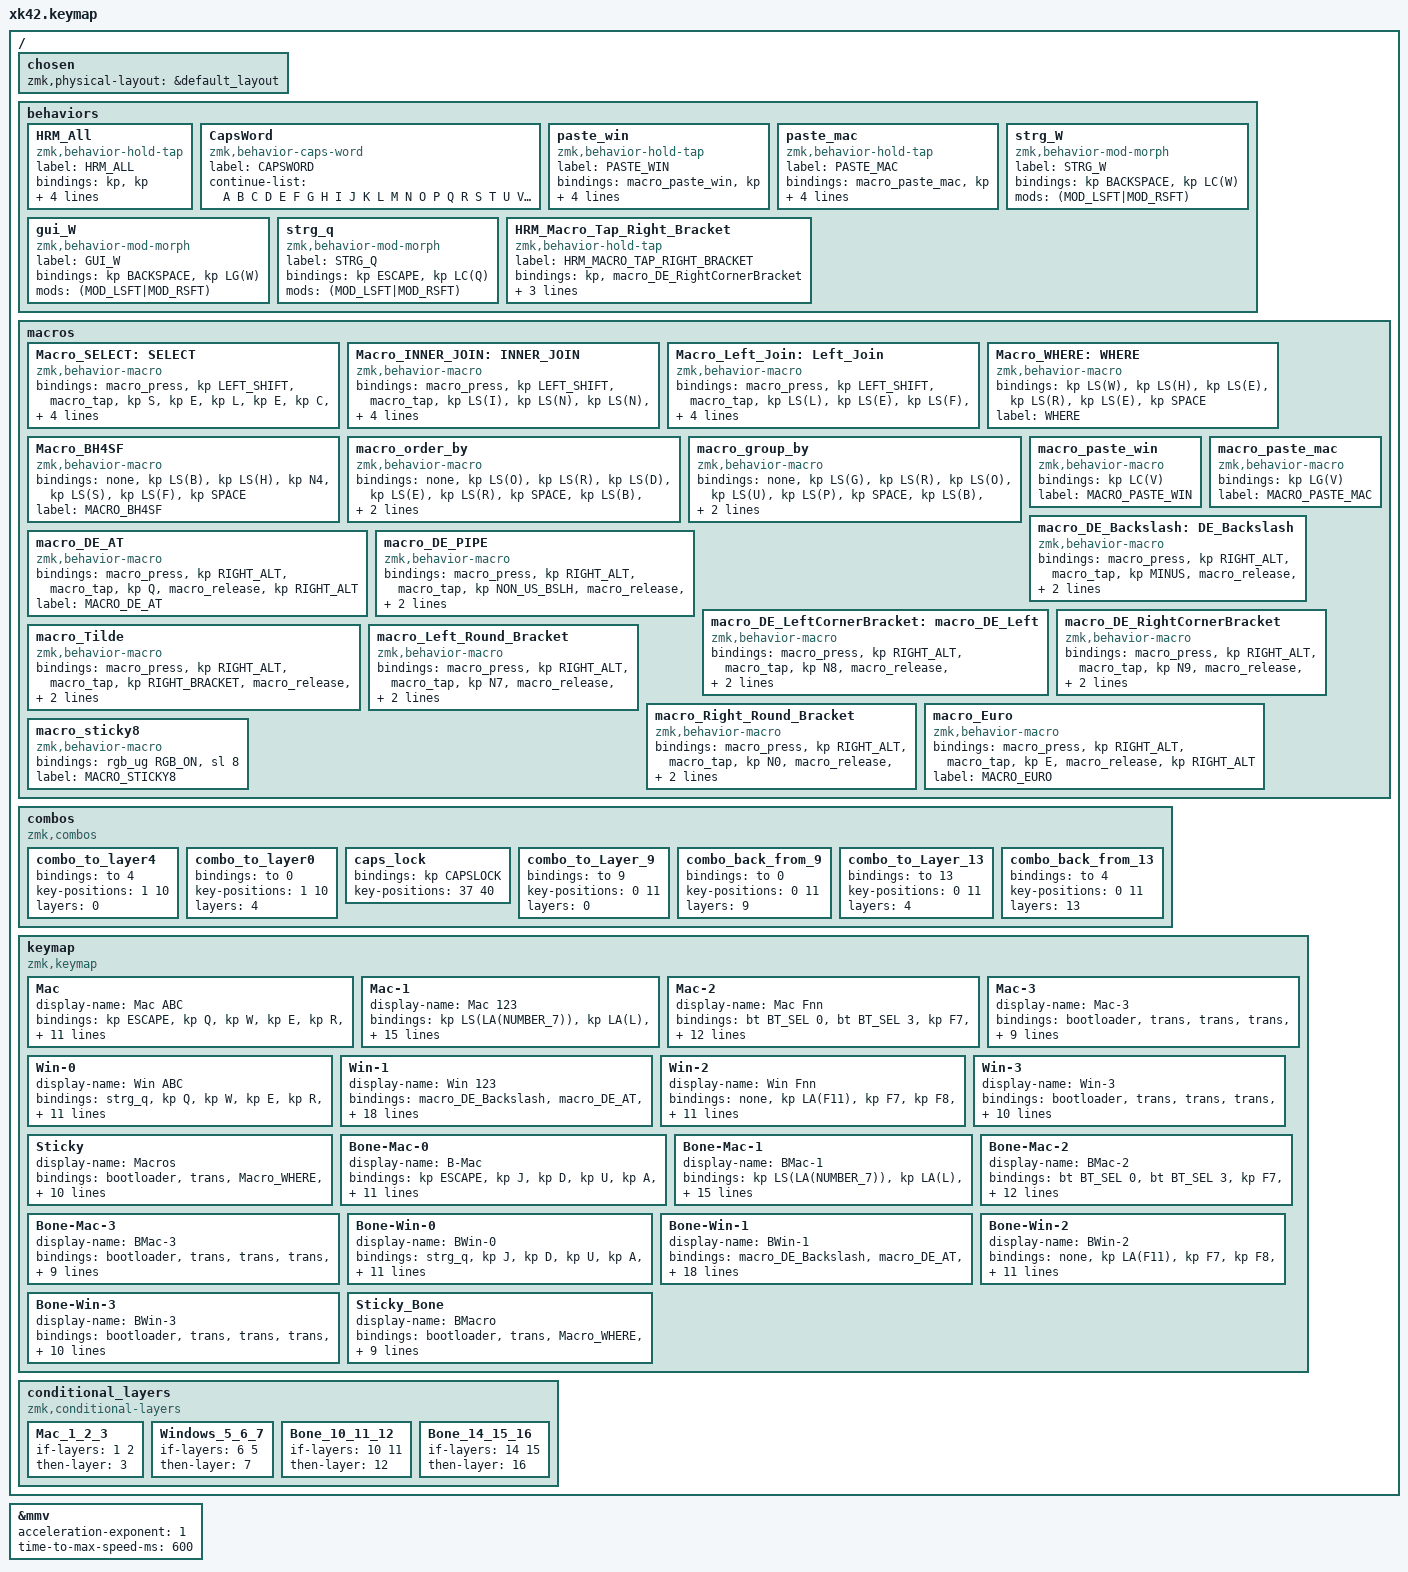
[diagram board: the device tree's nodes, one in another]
/*
 * Copyright (c) 2020 The ZMK Contributors
 *
 * SPDX-License-Identifier: MIT
 */

#define ZMK_POINTING_DEFAULT_MOVE_VAL 1500

#include <behaviors.dtsi>
#include <dt-bindings/zmk/bt.h>
#include <dt-bindings/zmk/keys.h>
#include <dt-bindings/zmk/pointing.h>
#include <dt-bindings/zmk/rgb.h>
#include "keys_de.h"

&mmv {
    acceleration-exponent = <1>;
    time-to-max-speed-ms = <600>;
};

/ {
    chosen { zmk,physical-layout = &default_layout; };

    behaviors {
        HRM_All: HRM_All {
            compatible = "zmk,behavior-hold-tap";
            label = "HRM_ALL";
            bindings = <&kp>, <&kp>;

            #binding-cells = <2>;
            tapping-term-ms = <200>;
            flavor = "balanced";
            require-prior-idle-ms = <150>;
            quick-tap-ms = <125>;
        };

        CapsWord: CapsWord {
            compatible = "zmk,behavior-caps-word";
            label = "CAPSWORD";
            #binding-cells = <0>;
            continue-list = <A B C D E F G H I J K L M N O P Q R S T U V W X Y Z SLASH QUESTION>;
        };

        paste_win: paste_win {
            compatible = "zmk,behavior-hold-tap";
            label = "PASTE_WIN";
            bindings = <&macro_paste_win>, <&kp>;

            #binding-cells = <2>;
            tapping-term-ms = <175>;
            flavor = "tap-preferred";
            require-prior-idle-ms = <125>;
            quick-tap-ms = <125>;
        };

        paste_mac: paste_mac {
            compatible = "zmk,behavior-hold-tap";
            label = "PASTE_MAC";
            bindings = <&macro_paste_mac>, <&kp>;

            #binding-cells = <2>;
            tapping-term-ms = <175>;
            flavor = "tap-preferred";
            require-prior-idle-ms = <125>;
            quick-tap-ms = <125>;
        };

        strg_W: strg_W {
            compatible = "zmk,behavior-mod-morph";
            label = "STRG_W";
            bindings = <&kp BACKSPACE>, <&kp LC(W)>;

            #binding-cells = <0>;
            mods = <(MOD_LSFT|MOD_RSFT)>;
        };

        gui_W: gui_W {
            compatible = "zmk,behavior-mod-morph";
            label = "GUI_W";
            bindings = <&kp BACKSPACE>, <&kp LG(W)>;

            #binding-cells = <0>;
            mods = <(MOD_LSFT|MOD_RSFT)>;
        };

        strg_q: strg_q {
            compatible = "zmk,behavior-mod-morph";
            label = "STRG_Q";
            bindings = <&kp ESCAPE>, <&kp LC(Q)>;

            #binding-cells = <0>;
            mods = <(MOD_LSFT|MOD_RSFT)>;
        };

        HRM_Macro_Tap_Right_Bracket: HRM_Macro_Tap_Right_Bracket {
            compatible = "zmk,behavior-hold-tap";
            label = "HRM_MACRO_TAP_RIGHT_BRACKET";
            bindings = <&kp>, <&macro_DE_RightCornerBracket>;

            #binding-cells = <2>;
            tapping-term-ms = <200>;
            flavor = "balanced";
            require-prior-idle-ms = <125>;
        };
    };

    macros {
        Macro_SELECT: SELECT {
            compatible = "zmk,behavior-macro";
            #binding-cells = <0>;
            bindings =
                <&macro_press>,
                <&kp LEFT_SHIFT>,
                <&macro_tap>,
                <&kp S &kp E &kp L &kp E &kp C &kp T &kp SPACE &kp DE_STAR &kp SPACE &kp F &kp R &kp O &kp M &kp SPACE>,
                <&macro_release>,
                <&kp LEFT_SHIFT &rgb_ug RGB_OFF>;

            label = "SELECT";
        };

        Macro_INNER_JOIN: INNER_JOIN {
            compatible = "zmk,behavior-macro";
            #binding-cells = <0>;
            bindings =
                <&macro_press>,
                <&kp LEFT_SHIFT>,
                <&macro_tap>,
                <&kp LS(I) &kp LS(N) &kp LS(N) &kp LS(E) &kp LS(R) &kp SPACE &kp LS(J) &kp LS(O) &kp LS(I) &kp LS(N) &kp SPACE>,
                <&macro_release>,
                <&kp LEFT_SHIFT &rgb_ug RGB_OFF>;

            label = "INNER_JOIN";
        };

        Macro_Left_Join: Left_Join {
            compatible = "zmk,behavior-macro";
            #binding-cells = <0>;
            bindings =
                <&macro_press>,
                <&kp LEFT_SHIFT>,
                <&macro_tap>,
                <&kp LS(L) &kp LS(E) &kp LS(F) &kp LS(T) &kp SPACE &kp LS(J) &kp LS(O) &kp LS(I) &kp LS(N) &kp SPACE>,
                <&macro_release>,
                <&kp LEFT_SHIFT>;

            label = "LEFT_JOIN";
        };

        Macro_WHERE: WHERE {
            compatible = "zmk,behavior-macro";
            #binding-cells = <0>;
            bindings = <&kp LS(W) &kp LS(H) &kp LS(E) &kp LS(R) &kp LS(E) &kp SPACE>;
            label = "WHERE";
        };

        Macro_BH4SF: Macro_BH4SF {
            compatible = "zmk,behavior-macro";
            #binding-cells = <0>;
            bindings = <&none &kp LS(B) &kp LS(H) &kp N4 &kp LS(S) &kp LS(F) &kp SPACE>;
            label = "MACRO_BH4SF";
        };

        macro_order_by: macro_order_by {
            compatible = "zmk,behavior-macro";
            #binding-cells = <0>;
            bindings = <&none &kp LS(O) &kp LS(R) &kp LS(D) &kp LS(E) &kp LS(R) &kp SPACE &kp LS(B) &kp LS(DE_Y)>;
            label = "MACRO_ORDER_BY";
        };

        macro_group_by: macro_group_by {
            compatible = "zmk,behavior-macro";
            #binding-cells = <0>;
            bindings = <&none &kp LS(G) &kp LS(R) &kp LS(O) &kp LS(U) &kp LS(P) &kp SPACE &kp LS(B) &kp LS(DE_Y)>;
            label = "MACRO_GROUP_BY";
        };

        macro_paste_win: macro_paste_win {
            compatible = "zmk,behavior-macro";
            #binding-cells = <0>;
            bindings = <&kp LC(V)>;
            label = "MACRO_PASTE_WIN";
        };

        macro_paste_mac: macro_paste_mac {
            compatible = "zmk,behavior-macro";
            #binding-cells = <0>;
            bindings = <&kp LG(V)>;
            label = "MACRO_PASTE_MAC";
        };

        macro_DE_Backslash: DE_Backslash {
            compatible = "zmk,behavior-macro";
            #binding-cells = <0>;
            bindings =
                <&macro_press>,
                <&kp RIGHT_ALT>,
                <&macro_tap>,
                <&kp MINUS>,
                <&macro_release>,
                <&kp RIGHT_ALT>;

            label = "DE_BACKSLASH";
        };

        macro_DE_AT: macro_DE_AT {
            compatible = "zmk,behavior-macro";
            #binding-cells = <0>;
            bindings =
                <&macro_press>,
                <&kp RIGHT_ALT>,
                <&macro_tap>,
                <&kp Q>,
                <&macro_release>,
                <&kp RIGHT_ALT>;

            label = "MACRO_DE_AT";
        };

        macro_DE_PIPE: macro_DE_PIPE {
            compatible = "zmk,behavior-macro";
            #binding-cells = <0>;
            bindings =
                <&macro_press>,
                <&kp RIGHT_ALT>,
                <&macro_tap>,
                <&kp NON_US_BSLH>,
                <&macro_release>,
                <&kp RIGHT_ALT>;

            label = "MACRO_DE_PIPE";
        };

        macro_DE_LeftCornerBracket: macro_DE_Left {
            compatible = "zmk,behavior-macro";
            #binding-cells = <0>;
            bindings =
                <&macro_press>,
                <&kp RIGHT_ALT>,
                <&macro_tap>,
                <&kp N8>,
                <&macro_release>,
                <&kp RIGHT_ALT>;

            label = "MACRO_DE_LEFT";
        };

        macro_DE_RightCornerBracket: macro_DE_RightCornerBracket {
            compatible = "zmk,behavior-macro";
            #binding-cells = <0>;
            bindings =
                <&macro_press>,
                <&kp RIGHT_ALT>,
                <&macro_tap>,
                <&kp N9>,
                <&macro_release>,
                <&kp RIGHT_ALT>;

            label = "MACRO_DE_RIGHTCORNERBRACKET";
        };

        macro_Tilde: macro_Tilde {
            compatible = "zmk,behavior-macro";
            #binding-cells = <0>;
            bindings =
                <&macro_press>,
                <&kp RIGHT_ALT>,
                <&macro_tap>,
                <&kp RIGHT_BRACKET>,
                <&macro_release>,
                <&kp RIGHT_ALT>;

            label = "MACRO_TILDE";
        };

        macro_Left_Round_Bracket: macro_Left_Round_Bracket {
            compatible = "zmk,behavior-macro";
            #binding-cells = <0>;
            bindings =
                <&macro_press>,
                <&kp RIGHT_ALT>,
                <&macro_tap>,
                <&kp N7>,
                <&macro_release>,
                <&kp RIGHT_ALT>;

            label = "MACRO_LEFT_ROUND_BRACKET";
        };

        macro_Right_Round_Bracket: macro_Right_Round_Bracket {
            compatible = "zmk,behavior-macro";
            #binding-cells = <0>;
            bindings =
                <&macro_press>,
                <&kp RIGHT_ALT>,
                <&macro_tap>,
                <&kp N0>,
                <&macro_release>,
                <&kp RIGHT_ALT>;

            label = "MACRO_RIGHT_ROUND_BRACKET";
        };

        macro_Euro: macro_Euro {
            compatible = "zmk,behavior-macro";
            #binding-cells = <0>;
            bindings =
                <&macro_press>,
                <&kp RIGHT_ALT>,
                <&macro_tap>,
                <&kp E>,
                <&macro_release>,
                <&kp RIGHT_ALT>;

            label = "MACRO_EURO";
        };

        macro_sticky8: macro_sticky8 {
            compatible = "zmk,behavior-macro";
            #binding-cells = <0>;
            bindings = <&rgb_ug RGB_ON &sl 8>;
            label = "MACRO_STICKY8";
        };
    };

    combos {
        compatible = "zmk,combos";

        // Wechselt zwischen den Haupt-Layern (Mac <-> Win)
        // Ursprünglich 1 & 12 -> Jetzt angepasst auf xk42 Matrix

        combo_to_layer4 {
            bindings = <&to 4>;
            key-positions = <1 10>;
            layers = <0>;
        };

        combo_to_layer0 {
            bindings = <&to 0>;
            key-positions = <1 10>;
            layers = <4>;
        };

        // CapsLock Combo: Geändert von 41/44 auf zwei erreichbare Tasten (z.B. die beiden innersten Daumentasten)
        // Beim xk42 sind das oft 37 und 38.

        caps_lock {
            bindings = <&kp CAPSLOCK>;
            key-positions = <37 40>;
        };

        // System-Wechsel (Bone Layer)

        combo_to_Layer_9 {
            bindings = <&to 9>;
            key-positions = <0 11>;
            layers = <0>;
        };

        combo_back_from_9 {
            bindings = <&to 0>;
            key-positions = <0 11>;
            layers = <9>;
        };

        combo_to_Layer_13 {
            bindings = <&to 13>;
            key-positions = <0 11>;
            layers = <4>;
        };

        combo_back_from_13 {
            bindings = <&to 4>;
            key-positions = <0 11>;
            layers = <13>;
        };
    };

    keymap {
        compatible = "zmk,keymap";

        Mac {
            display-name = "Mac ABC";
            bindings = <
&kp ESCAPE  &kp Q  &kp W  &kp E  &kp R  &kp T  &kp DE_Z  &kp U  &kp I  &kp O  &kp P  &kp DE_U_UMLAUT  &kp TAB  &kp A  &HRM_All LEFT_ALT S  &HRM_All LCTRL D  &HRM_All LEFT_GUI F  &kp G  &kp H  &HRM_All RIGHT_GUI J  &HRM_All LCTRL K  &HRM_All LEFT_ALT L  &kp DE_O_UMLAUT  &kp DE_A_UMLAUT  &macro_sticky8  &kp DE_Y  &kp X  &HRM_All LG(C) C  &paste_mac 0 V  &kp B  &kp N  &kp M  &kp COMMA  &kp DOT  &kp DE_MINUS  &gui_W  &mo 1  &kp LEFT_SHIFT  &kp SPACE  &kp RET  &kp RIGHT_SHIFT  &mo 2
            >;
        };

        Mac-1 {
            display-name = "Mac 123";
            bindings = <
&kp LS(LA(NUMBER_7))  &kp LA(L)  &kp DE_DOUBLE_QUOTES  &kp DE_LEFT_PARENTHESIS  &kp DE_RIGHT_PARENTHESIS  &kp DE_DOLLAR  &kp DE_ACUTE  &kp N7  &kp N8  &kp N9  &kp N0  &kp DE_SHARP_S  &kp LA(NUMBER_7)  &kp LA(NUMBER_5)  &HRM_All LALT LA(NUMBER_6)  &HRM_All LCTRL DE_HASH  &kp LEFT_GUI  &kp DE_EURO  &kp DE_SINGLE_QUOTE  &HRM_All RIGHT_GUI NUMBER_4  &HRM_All RCTRL NUMBER_5  &HRM_All RALT N6  &kp DE_PLUS  &kp DE_SLASH  &kp LA(N)  &kp LA(NUMBER_8)  &kp LA(NUMBER_9)  &kp NON_US_BSLH  &kp LS(NON_US_BSLH)  &kp DE_PERCENT  &kp DE_AMPERSAND  &kp N1  &kp N2  &kp N3  &kp N0  &kp DE_ASTERISK  &trans  &trans  &trans  &kp DE_EQUAL  &trans  &trans
            >;
        };

        Mac-2 {
            display-name = "Mac Fnn";
            bindings = <
&bt BT_SEL 0  &bt BT_SEL 3  &kp F7  &kp F8  &kp F9  &kp F10  &kp C_PAUSE  &kp EXCL  &kp UP  &kp LG(UP)  &none  &rgb_ug RGB_ON  &bt BT_SEL 1  &bt BT_SEL 4  &HRM_All LEFT_ALT F4  &HRM_All LCTRL F5  &HRM_All LGUI F6  &kp LG(RIGHT_BRACKET)  &kp LG(LS(NUMBER_4))  &kp LEFT  &kp LG(LEFT_ARROW)  &kp RIGHT  &kp LG(RIGHT)  &rgb_ug RGB_OFF  &bt BT_SEL 2  &bt BT_CLR  &kp F1  &kp F2  &kp F3  &kp LG(SLASH)  &none  &kp LA(LS(N6))  &kp DOWN  &kp LG(DOWN)  &kp LS(LA(DE_ACUTE))  &kp DELETE  &trans  &trans  &kp DE_QUESTION  &trans  &trans  &trans
            >;
        };

        Mac-3 {
            display-name = "Mac-3";
            bindings = <
&bootloader  &trans  &trans  &trans  &trans  &trans  &trans  &msc SCRL_DOWN  &mmv MOVE_UP  &kp PAGE_UP  &trans  &trans  &trans  &trans  &mkp MB3  &mkp MB1  &mkp MB2  &trans  &trans  &mmv MOVE_LEFT  &mkp MB1  &mmv MOVE_RIGHT  &mkp MB2  &trans  &trans  &trans  &trans  &trans  &trans  &trans  &trans  &msc SCRL_UP  &mmv MOVE_DOWN  &kp PAGE_DOWN  &trans  &trans  &trans  &trans  &trans  &trans  &trans  &trans
            >;
        };

        Win-0 {
            display-name = "Win ABC";
            bindings = <
&strg_q  &kp Q  &kp W  &kp E  &kp R  &kp T  &kp DE_Z  &kp U  &kp I  &kp O  &kp P  &kp DE_U_UMLAUT  &kp TAB  &kp A  &HRM_All LEFT_GUI S  &HRM_All LCTRL D  &HRM_All LEFT_ALT F  &kp G  &kp H  &HRM_All LALT J  &HRM_All LCTRL K  &HRM_All RIGHT_GUI L  &kp DE_O_UMLAUT  &kp DE_A_UMLAUT  &sl 8  &kp DE_Y  &kp X  &HRM_All LC(C) C  &paste_win 0 V  &kp B  &kp N  &kp M  &kp COMMA  &kp DOT  &kp DE_MINUS  &strg_W  &mo 5  &kp LEFT_SHIFT  &kp SPACE  &kp RET  &kp RIGHT_SHIFT  &mo 6
            >;
        };

        Win-1 {
            display-name = "Win 123";
            bindings = <
&macro_DE_Backslash  &macro_DE_AT  &kp DE_DOUBLE_QUOTES  &kp DE_LEFT_PARENTHESIS  &kp DE_RIGHT_PARENTHESIS  &kp DE_DOLLAR  &kp DE_ACUTE  &kp N7  &kp N8  &kp N9  &kp DE_CARET  &kp DE_SHARP_S  &macro_DE_PIPE  &macro_DE_LeftCornerBracket  &HRM_Macro_Tap_Right_Bracket LEFT_GUI 0  &HRM_All LCTRL DE_HASH  &HRM_All LEFT_ALT INS  &macro_Euro  &kp DE_SINGLE_QUOTE  &HRM_All LALT NUMBER_4  &HRM_All RCTRL NUMBER_5  &HRM_All RIGHT_GUI N6  &kp DE_PLUS  &kp DE_SLASH  &macro_Tilde  &macro_Left_Round_Bracket  &macro_Right_Round_Bracket  &kp DE_LESS_THAN  &kp DE_GREATER_THAN  &kp DE_PERCENT  &kp DE_AMPERSAND  &kp N1  &kp N2  &kp N3  &kp N0  &kp DE_ASTERISK  &trans  &trans  &trans  &kp DE_EQUAL  &trans  &trans
            >;
        };

        Win-2 {
            display-name = "Win Fnn";
            bindings = <
&none  &kp LA(F11)  &kp F7  &kp F8  &kp F9  &kp F10  &kp PAUSE_BREAK  &kp DE_EXCL  &kp UP  &kp LC(HOME)  &none  &rgb_ug RGB_ON  &none  &kp LS(F8)  &HRM_All LEFT_GUI F4  &HRM_All LCTRL F5  &HRM_All LEFT_ALT F6  &mt LCTRL DE_PLUS  &kp PRINTSCREEN  &kp LEFT  &kp HOME  &kp RIGHT  &kp END  &rgb_ug RGB_OFF  &none  &none  &kp F1  &kp F2  &kp F3  &mt LCTRL DE_MINUS  &none  &kp DE_CARET  &kp DOWN  &kp LC(END)  &kp DE_DEGREE  &kp DELETE  &trans  &trans  &kp DE_QUESTION  &trans  &trans  &trans
            >;
        };

        Win-3 {
            display-name = "Win-3";
            bindings = <
&bootloader  &trans  &trans  &trans  &trans  &trans  &trans  &msc SCRL_UP  &mmv MOVE_UP  &kp PAGE_UP  &trans  &rgb_ug RGB_EFF  &trans  &trans  &mkp MB3  &mkp MB1  &mkp MB2  &trans  &trans  &mmv MOVE_LEFT  &mkp MB1  &mmv MOVE_RIGHT  &mkp MB2  &rgb_ug RGB_EFR  &trans  &trans  &trans  &trans  &trans  &trans  &trans  &msc SCRL_DOWN  &mmv MOVE_DOWN  &kp PAGE_DOWN  &trans  &trans  &trans  &trans  &trans  &trans  &trans  &trans
            >;
        };

        Sticky {
            display-name = "Macros";
            bindings = <
&bootloader  &trans  &Macro_WHERE  &trans  &trans  &trans  &trans  &trans  &Macro_INNER_JOIN  &macro_order_by  &trans  &bootloader  &trans  &trans  &Macro_SELECT  &trans  &trans  &macro_group_by  &trans  &trans  &trans  &Macro_Left_Join  &rgb_ug RGB_SPI  &rgb_ug RGB_EFF  &CapsWord  &trans  &trans  &trans  &trans  &Macro_BH4SF  &trans  &trans  &trans  &trans  &rgb_ug RGB_SPD  &rgb_ug RGB_EFR  &trans  &trans  &trans  &trans  &trans  &trans
            >;
        };

        Bone-Mac-0 {
            display-name = "B-Mac";
            bindings = <
&kp ESCAPE  &kp J  &kp D  &kp U  &kp A  &kp X  &kp P  &kp H  &kp L  &kp M  &kp W  &kp DE_MINUS  &kp TAB  &HRM_All LG(C) C  &HRM_All LEFT_ALT T  &HRM_All LCTRL I  &HRM_All LEFT_GUI E  &kp O  &kp B  &HRM_All RIGHT_GUI N  &HRM_All LCTRL R  &HRM_All LEFT_ALT S  &kp G  &kp Q  &sl 17  &kp F  &paste_mac 0 V  &kp DE_U_UMLAUT  &kp DE_A_UMLAUT  &kp DE_O_UMLAUT  &kp DE_Y  &kp DE_Z  &kp COMMA  &kp DOT  &kp K  &gui_W  &mo 10  &kp LEFT_SHIFT  &kp SPACE  &kp RET  &kp RIGHT_SHIFT  &mo 11
            >;
        };

        Bone-Mac-1 {
            display-name = "BMac-1";
            bindings = <
&kp LS(LA(NUMBER_7))  &kp LA(L)  &kp DE_DOUBLE_QUOTES  &kp DE_LEFT_PARENTHESIS  &kp DE_RIGHT_PARENTHESIS  &kp DE_DOLLAR  &kp DE_ACUTE  &kp N7  &kp N8  &kp N9  &kp N0  &kp DE_SHARP_S  &kp LA(NUMBER_7)  &kp LA(NUMBER_5)  &HRM_All LALT LA(NUMBER_6)  &HRM_All LCTRL DE_HASH  &kp LEFT_GUI  &kp DE_EURO  &kp DE_SINGLE_QUOTE  &HRM_All RIGHT_GUI NUMBER_4  &HRM_All RCTRL NUMBER_5  &HRM_All RALT N6  &kp DE_PLUS  &kp DE_SLASH  &kp LA(N)  &kp LA(NUMBER_8)  &kp LA(NUMBER_9)  &kp NON_US_BSLH  &kp LS(NON_US_BSLH)  &kp DE_PERCENT  &kp DE_AMPERSAND  &kp N1  &kp N2  &kp N3  &kp N0  &kp DE_ASTERISK  &trans  &trans  &trans  &kp DE_EQUAL  &trans  &trans
            >;
        };

        Bone-Mac-2 {
            display-name = "BMac-2";
            bindings = <
&bt BT_SEL 0  &bt BT_SEL 3  &kp F7  &kp F8  &kp F9  &kp F10  &kp C_PAUSE  &kp EXCL  &kp UP  &kp LG(UP)  &none  &rgb_ug RGB_ON  &bt BT_SEL 1  &bt BT_SEL 4  &HRM_All LEFT_ALT F4  &HRM_All LCTRL F5  &HRM_All LGUI F6  &kp LG(RIGHT_BRACKET)  &kp LG(LS(NUMBER_4))  &kp LEFT  &kp LG(LEFT_ARROW)  &kp RIGHT  &kp LG(RIGHT)  &rgb_ug RGB_OFF  &bt BT_SEL 2  &bt BT_CLR  &kp F1  &kp F2  &kp F3  &kp LG(SLASH)  &none  &kp LS(LA(N6))  &kp DOWN  &kp LG(DOWN)  &kp DELETE  &kp DELETE  &trans  &trans  &kp DE_QUESTION  &trans  &trans  &trans
            >;
        };

        Bone-Mac-3 {
            display-name = "BMac-3";
            bindings = <
&bootloader  &trans  &trans  &trans  &trans  &trans  &trans  &msc SCRL_UP  &mmv MOVE_UP  &kp PAGE_UP  &trans  &trans  &trans  &trans  &mkp MB3  &mkp MB1  &mkp MB2  &trans  &trans  &mmv MOVE_LEFT  &mkp MB1  &mmv MOVE_RIGHT  &mkp MB2  &trans  &trans  &trans  &trans  &trans  &trans  &trans  &trans  &msc SCRL_DOWN  &mmv MOVE_DOWN  &kp PAGE_DOWN  &trans  &trans  &trans  &trans  &trans  &trans  &trans  &trans
            >;
        };

        Bone-Win-0 {
            display-name = "BWin-0";
            bindings = <
&strg_q  &kp J  &kp D  &kp U  &kp A  &kp X  &kp P  &kp H  &kp L  &kp M  &kp W  &kp DE_MINUS  &kp TAB  &HRM_All LC(C) C  &HRM_All LEFT_GUI T  &HRM_All LCTRL I  &HRM_All LEFT_ALT E  &kp O  &kp B  &HRM_All LEFT_ALT N  &HRM_All LCTRL R  &HRM_All RIGHT_GUI S  &kp G  &kp Q  &sl 17  &kp F  &paste_win 0 V  &kp DE_U_UMLAUT  &kp DE_A_UMLAUT  &kp DE_O_UMLAUT  &kp DE_Y  &kp DE_Z  &kp COMMA  &kp DOT  &kp K  &strg_W  &mo 14  &kp LEFT_SHIFT  &kp SPACE  &kp RET  &kp RIGHT_SHIFT  &mo 15
            >;
        };

        Bone-Win-1 {
            display-name = "BWin-1";
            bindings = <
&macro_DE_Backslash  &macro_DE_AT  &kp DE_DOUBLE_QUOTES  &kp DE_LEFT_PARENTHESIS  &kp DE_RIGHT_PARENTHESIS  &kp DE_DOLLAR  &kp DE_ACUTE  &kp N7  &kp N8  &kp N9  &kp DE_CARET  &kp DE_SHARP_S  &macro_DE_PIPE  &macro_DE_LeftCornerBracket  &HRM_Macro_Tap_Right_Bracket LEFT_GUI 0  &HRM_All LCTRL DE_HASH  &HRM_All LEFT_ALT INS  &macro_Euro  &kp DE_SINGLE_QUOTE  &HRM_All LALT NUMBER_4  &HRM_All RCTRL NUMBER_5  &HRM_All RIGHT_GUI N6  &kp DE_PLUS  &kp DE_SLASH  &macro_Tilde  &macro_Left_Round_Bracket  &macro_Right_Round_Bracket  &kp DE_LESS_THAN  &kp DE_GREATER_THAN  &kp DE_PERCENT  &kp DE_AMPERSAND  &kp N1  &kp N2  &kp N3  &kp N0  &kp DE_ASTERISK  &trans  &trans  &trans  &kp DE_EQUAL  &trans  &trans
            >;
        };

        Bone-Win-2 {
            display-name = "BWin-2";
            bindings = <
&none  &kp LA(F11)  &kp F7  &kp F8  &kp F9  &kp F10  &kp PAUSE_BREAK  &kp DE_EXCL  &kp UP  &kp LC(HOME)  &none  &rgb_ug RGB_ON  &none  &kp LS(F8)  &HRM_All LEFT_GUI F4  &HRM_All LCTRL F5  &HRM_All LEFT_ALT F6  &mt LCTRL DE_PLUS  &kp PRINTSCREEN  &kp LEFT  &kp HOME  &kp RIGHT  &kp END  &rgb_ug RGB_OFF  &none  &none  &kp F1  &kp F2  &kp F3  &mt LCTRL DE_MINUS  &none  &kp DE_CARET  &kp DOWN_ARROW  &kp LC(END)  &kp DE_DEGREE  &kp DELETE  &trans  &trans  &kp DE_QUESTION  &trans  &trans  &trans
            >;
        };

        Bone-Win-3 {
            display-name = "BWin-3";
            bindings = <
&bootloader  &trans  &trans  &trans  &trans  &trans  &trans  &msc SCRL_UP  &mmv MOVE_UP  &kp PAGE_UP  &trans  &rgb_ug RGB_EFF  &trans  &trans  &mkp MB3  &mkp MB1  &mkp MB2  &trans  &trans  &mmv MOVE_LEFT  &mkp MB1  &mmv MOVE_RIGHT  &mkp MB2  &rgb_ug RGB_EFR  &trans  &trans  &trans  &trans  &trans  &trans  &trans  &msc SCRL_DOWN  &mmv MOVE_DOWN  &kp PAGE_DOWN  &trans  &trans  &trans  &trans  &trans  &trans  &trans  &trans
            >;
        };

        Sticky_Bone {
            display-name = "BMacro";
            bindings = <
&bootloader  &trans  &Macro_WHERE  &trans  &trans  &trans  &trans  &trans  &Macro_Left_Join  &trans  &Macro_WHERE  &bootloader  &trans  &trans  &trans  &Macro_INNER_JOIN  &trans  &macro_order_by  &Macro_BH4SF  &trans  &none  &Macro_SELECT  &macro_group_by  &rgb_ug RGB_EFF  &CapsWord  &trans  &trans  &trans  &trans  &trans  &trans  &trans  &trans  &trans  &trans  &rgb_ug RGB_EFR  &trans  &trans  &trans  &trans  &trans  &trans
            >;
        };
    };

    conditional_layers {
        compatible = "zmk,conditional-layers";

        Mac_1_2_3 {
            if-layers = <1 2>;
            then-layer = <3>;
        };

        Windows_5_6_7 {
            if-layers = <6 5>;
            then-layer = <7>;
        };

        Bone_10_11_12 {
            if-layers = <10 11>;
            then-layer = <12>;
        };

        Bone_14_15_16 {
            if-layers = <14 15>;
            then-layer = <16>;
        };
    };
};
